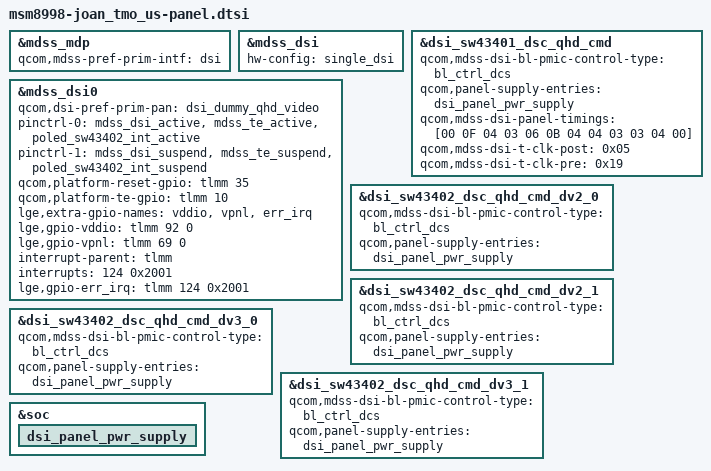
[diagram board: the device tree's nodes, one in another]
/* Copyright (c) 2016, The Linux Foundation. All rights reserved.
 *
 * This program is free software; you can redistribute it and/or modify
 * it under the terms of the GNU General Public License version 2 and
 * only version 2 as published by the Free Software Foundation.
 *
 * This program is distributed in the hope that it will be useful,
 * but WITHOUT ANY WARRANTY; without even the implied warranty of
 * MERCHANTABILITY or FITNESS FOR A PARTICULAR PURPOSE.  See the
 * GNU General Public License for more details.
 */

#include "../../dsi-panel-sw43401-dsc-qhd-cmd.dtsi"
#include "../../dsi-panel-sw43402-dsc-qhd-cmd-dv2_0.dtsi"
#include "../../dsi-panel-sw43402-dsc-qhd-cmd-dv2_1.dtsi"
#include "../../dsi-panel-sw43402-dsc-qhd-cmd-dv3_0.dtsi"
#include "../../dsi-panel-sw43402-dsc-qhd-cmd-dv3_1.dtsi"
#include "../../dsi-panel-dummy-qhd-video.dtsi"

&mdss_mdp {
	qcom,mdss-pref-prim-intf = "dsi";
};

&mdss_dsi {
        hw-config = "single_dsi";
};

&mdss_dsi0 {
	qcom,dsi-pref-prim-pan = <&dsi_dummy_qhd_video>;
	pinctrl-names = "mdss_default", "mdss_sleep";
	pinctrl-0 = <&mdss_dsi_active &mdss_te_active &poled_sw43402_int_active>;
	pinctrl-1 = <&mdss_dsi_suspend &mdss_te_suspend &poled_sw43402_int_suspend>;
	qcom,platform-reset-gpio = <&tlmm 35 0>;
	qcom,platform-te-gpio = <&tlmm 10 0>;
	/delete-property/wqhd-vddio-supply;
	lge,extra-gpio-names = "vddio", "vpnl", "err_irq";
	lge,gpio-vddio = <&tlmm 92 0>;
	lge,gpio-vpnl =  <&tlmm 69 0>;

	interrupt-parent = <&tlmm>;
	interrupts = <124 0x2001>; /*IRQF_ONESHOT | IRQF_TRIGGER_RISING*/
	lge,gpio-err_irq =  <&tlmm 124 0x2001>; /* IRQF_ONESHOT | IRQF_TRIGGER_RISING */
};

&dsi_sw43401_dsc_qhd_cmd {
	qcom,mdss-dsi-bl-pmic-control-type = "bl_ctrl_dcs";
	/* qcom,cont-splash-enabled; */
	qcom,panel-supply-entries = <&dsi_panel_pwr_supply>;

	qcom,mdss-dsi-panel-timings = [00 0F 04 03 06 0B 04 04 03 03 04 00];
	qcom,mdss-dsi-t-clk-post = <0x05>;
	qcom,mdss-dsi-t-clk-pre = <0x19>;
};

&dsi_sw43402_dsc_qhd_cmd_dv2_0 {
	qcom,mdss-dsi-bl-pmic-control-type = "bl_ctrl_dcs";
	/* qcom,cont-splash-enabled; */
	qcom,panel-supply-entries = <&dsi_panel_pwr_supply>;
};

&dsi_sw43402_dsc_qhd_cmd_dv2_1 {
	qcom,mdss-dsi-bl-pmic-control-type = "bl_ctrl_dcs";
	/* qcom,cont-splash-enabled; */
	qcom,panel-supply-entries = <&dsi_panel_pwr_supply>;
};

&dsi_sw43402_dsc_qhd_cmd_dv3_0 {
	qcom,mdss-dsi-bl-pmic-control-type = "bl_ctrl_dcs";
	/* qcom,cont-splash-enabled; */
	qcom,panel-supply-entries = <&dsi_panel_pwr_supply>;
};

&dsi_sw43402_dsc_qhd_cmd_dv3_1 {
	qcom,mdss-dsi-bl-pmic-control-type = "bl_ctrl_dcs";
	/* qcom,cont-splash-enabled; */
	qcom,panel-supply-entries = <&dsi_panel_pwr_supply>;
};

&soc {
	dsi_panel_pwr_supply: dsi_panel_pwr_supply {
		#address-cells = <1>;
		#size-cells = <0>;
		/delete-node/qcom,panel-supply-entry@0;
		/delete-node/qcom,panel-supply-entry@1;
		/delete-node/qcom,panel-supply-entry@2;
	};
};

/* End of overriding parameters in msm8998-mdss-panel.dtsi */
